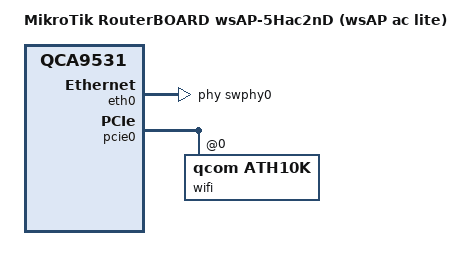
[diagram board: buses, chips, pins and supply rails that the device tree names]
// SPDX-License-Identifier: GPL-2.0-or-later OR MIT

#include "qca9533_mikrotik_routerboard-95x.dtsi"

/ {
	compatible = "mikrotik,routerboard-wsap-5hac2nd", "qca,qca9531";
	model = "MikroTik RouterBOARD wsAP-5Hac2nD (wsAP ac lite)";
};

&eth0 {
	status = "okay";

	phy-handle = <&swphy0>;

	gmac-config {
		device = <&gmac>;
		switch-phy-swap = <1>;
	};
};

&pcie0 {
 	status = "okay";

 	wifi@0,0 {
 		compatible = "qcom,ath10k";
 		reg = <0 0 0 0 0>;
 	};
};
